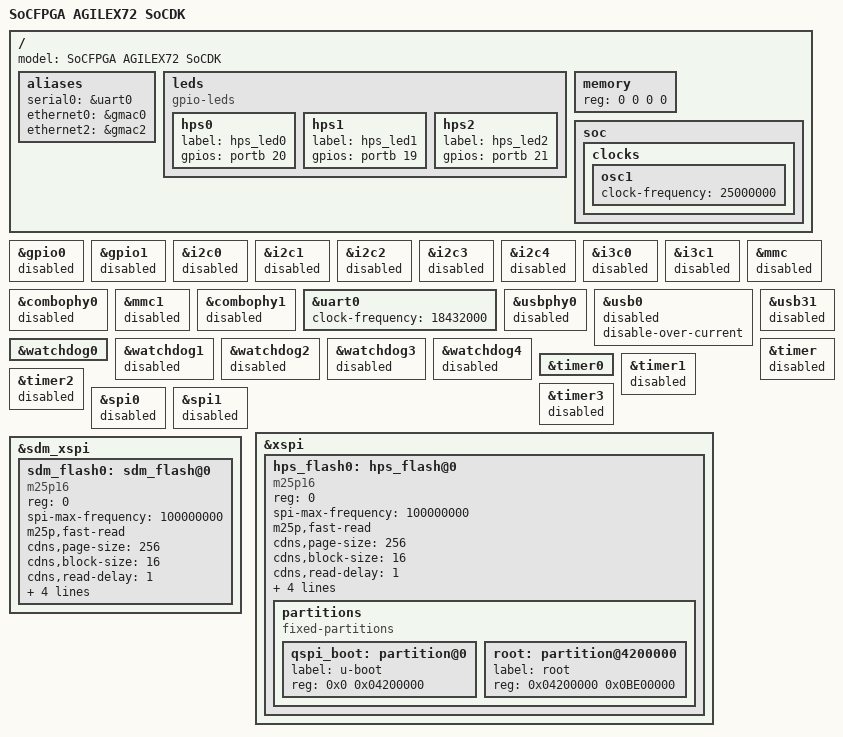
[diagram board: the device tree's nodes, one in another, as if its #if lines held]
// SPDX-License-Identifier:     GPL-2.0
/*
 * Copyright (C) 2025 Altera Corporation <www.altera.com>
 */
#include "socfpga_agilex72.dtsi"

/ {
	model = "SoCFPGA AGILEX72 SoCDK";

	aliases {
		serial0 = &uart0;
		ethernet0 = &gmac0;
		ethernet2 = &gmac2;
	};

	leds {
		compatible = "gpio-leds";
		hps0 {
			label = "hps_led0";
			gpios = <&portb 20 GPIO_ACTIVE_HIGH>;
		};

		hps1 {
			label = "hps_led1";
			gpios = <&portb 19 GPIO_ACTIVE_HIGH>;
		};

		hps2 {
			label = "hps_led2";
			gpios = <&portb 21 GPIO_ACTIVE_HIGH>;
		};
	};

	memory {
		device_type = "memory";
		/* We expect the bootloader to fill in the reg */
		reg = <0 0 0 0>;
	};

	soc {
		clocks {
			osc1 {
				clock-frequency = <25000000>;
			};
		};
	};
};

&gpio0 {
	status = "disabled";
};

&gpio1 {
	status = "disabled";
};

&i2c0 {
#ifdef CONFIG_TARGET_SOCFPGA_EMU
	status = "disabled";
#else
	status = "okay";
#endif
};

&i2c1 {
#ifdef CONFIG_TARGET_SOCFPGA_EMU
	status = "disabled";
#else
	status = "okay";
#endif
};

&i2c2 {
#ifdef CONFIG_TARGET_SOCFPGA_EMU
	status = "disabled";
#else
	status = "okay";
#endif
};

&i2c3 {
#ifdef CONFIG_TARGET_SOCFPGA_EMU
	status = "disabled";
#else
	status = "okay";
#endif
};

&i2c4 {
#ifdef CONFIG_TARGET_SOCFPGA_EMU
	status = "disabled";
#else
	status = "okay";
#endif
};

&i3c0 {
#ifdef CONFIG_TARGET_SOCFPGA_EMU
	status = "disabled";
#else
	status = "okay";
#endif
};

&i3c1 {
#ifdef CONFIG_TARGET_SOCFPGA_EMU
	status = "disabled";
#else
	status = "okay";
#endif
};

&mmc {
#ifdef CONFIG_TARGET_SOCFPGA_EMU
	status = "disabled";
#else
	status = "okay";
	no-1-8-v;
	/* sd-uhs-sdr50; */
	sdhci-caps = <0x00000000 0x0000c800>;
	sdhci-caps-mask = <0x00002007 0x0000ff00>;
#endif
};

&combophy0 {
#ifdef CONFIG_TARGET_SOCFPGA_EMU
	status = "disabled";
#else
	status = "okay";
#endif
};

&mmc1 {
#ifdef CONFIG_TARGET_SOCFPGA_EMU
	status = "disabled";
#else
	status = "okay";
	no-1-8-v;
	/* sd-uhs-sdr50; */
	sdhci-caps = <0x00000000 0x0000c800>;
	sdhci-caps-mask = <0x00002007 0x0000ff00>;
#endif
};

&combophy1 {
#ifdef CONFIG_TARGET_SOCFPGA_EMU
	status = "disabled";
#else
	status = "okay";
#endif
};

&uart0 {
	status = "okay";
#ifdef CONFIG_TARGET_SOCFPGA_EMU
	/* Emu settings */
	/delete-property/ clocks;
	clock-frequency = <18432000>;
#endif
};

&usbphy0 {
	status = "disabled";
};

&usb0 {
	status = "disabled";
	disable-over-current;
};

&usb31 {
	status = "disabled";
};

&watchdog0 {
	status = "okay";
};

&watchdog1 {
	status = "disabled";
};

&watchdog2 {
	status = "disabled";
};

&watchdog3 {
	status = "disabled";
};

&watchdog4 {
	status = "disabled";
};

&timer {
#ifdef CONFIG_TARGET_SOCFPGA_EMU
	status = "disabled";
#else
	status = "okay";
#endif
};

&timer0 {
	status = "okay";
};

&timer1 {
	status = "disabled";
};

&timer2 {
	status = "disabled";
};

&timer3 {
	status = "disabled";
};

&spi0 {
	status = "disabled";
};

&spi1 {
	status = "disabled";
};

&xspi {
	hps_flash0: hps_flash@0 {
		#address-cells = <1>;
		#size-cells = <1>;
		compatible = "m25p16";
		reg = <0>;
		spi-max-frequency = <100000000>;

		m25p,fast-read;
		cdns,page-size = <256>;
		cdns,block-size = <16>;
		cdns,read-delay = <1>;
		cdns,tshsl-ns = <50>;
		cdns,tsd2d-ns = <50>;
		cdns,tchsh-ns = <4>;
		cdns,tslch-ns = <4>;

		partitions {
			compatible = "fixed-partitions";
			#address-cells = <1>;
			#size-cells = <1>;

			qspi_boot: partition@0 {
				label = "u-boot";
				reg = <0x0 0x04200000>;
			};

			root: partition@4200000 {
				label = "root";
				reg = <0x04200000 0x0BE00000>;
			};
		};
	};
};

&sdm_xspi {
	sdm_flash0: sdm_flash@0 {
		#address-cells = <1>;
		#size-cells = <1>;
		compatible = "m25p16";
		reg = <0>;
		spi-max-frequency = <100000000>;

		m25p,fast-read;
		cdns,page-size = <256>;
		cdns,block-size = <16>;
		cdns,read-delay = <1>;
		cdns,tshsl-ns = <50>;
		cdns,tsd2d-ns = <50>;
		cdns,tchsh-ns = <4>;
		cdns,tslch-ns = <4>;
	};
};

